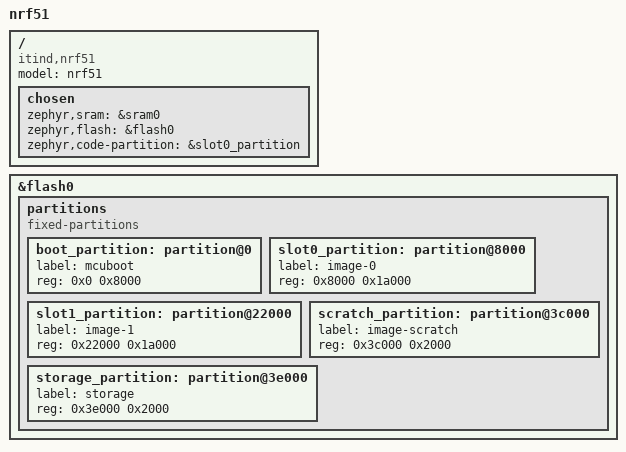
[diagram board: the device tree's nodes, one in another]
// Copyright (c) 2023 Nordic Semiconductor ASA
// SPDX-License-Identifier: Apache-2.0

/dts-v1/;
#include <nordic/nrf51822_qfaa.dtsi>

/ {
	model = "nrf51";
	compatible = "itind,nrf51";

	chosen {
		zephyr,sram = &sram0;
		zephyr,flash = &flash0;
		zephyr,code-partition = &slot0_partition;
	};
};

&flash0 {
	partitions {
		compatible = "fixed-partitions";
		#address-cells = <1>;
		#size-cells = <1>;

		boot_partition: partition@0 {
			label = "mcuboot";
			reg = <0x0 0x8000>;
		};
		slot0_partition: partition@8000 {
			label = "image-0";
			reg = <0x8000 0x1a000>;
		};
		slot1_partition: partition@22000 {
			label = "image-1";
			reg = <0x22000 0x1a000>;
		};
		scratch_partition: partition@3c000 {
			label = "image-scratch";
			reg = <0x3c000 0x2000>;
		};
		storage_partition: partition@3e000 {
			label = "storage";
			reg = <0x3e000 0x2000>;
		};
	};
};

